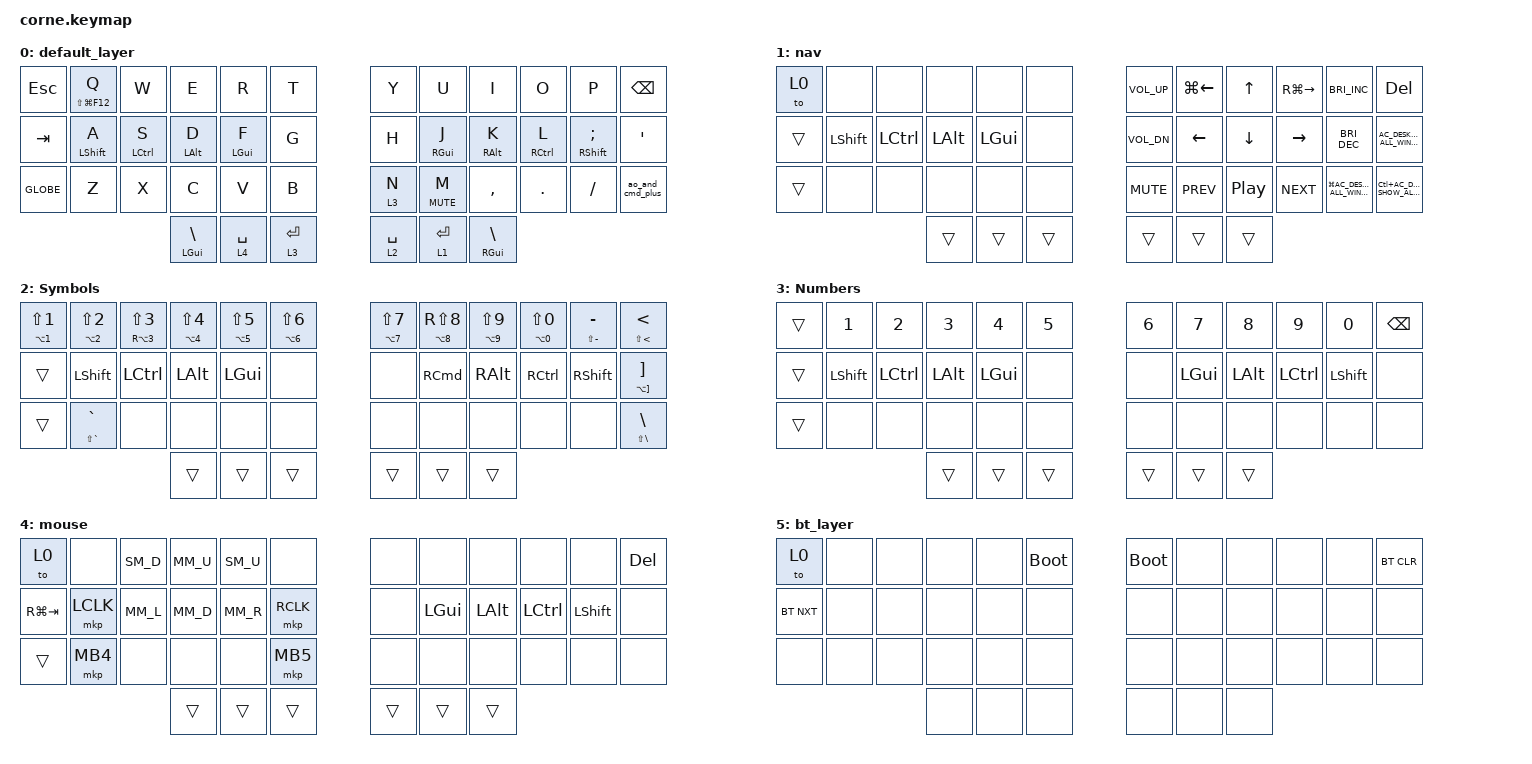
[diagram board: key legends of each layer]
/*
 * Copyright (c) 2020 The ZMK Contributors
 *
 * SPDX-License-Identifier: MIT
 */

#include <dt-bindings/zmk/mouse.h>
#include <behaviors.dtsi>
#include <dt-bindings/zmk/bt.h>
#include <dt-bindings/zmk/keys.h>
#include <dt-bindings/zmk/mouse.h>
#include <dt-bindings/zmk/pointing.h>
#include "mouse.dtsi"

/ {
    behaviors {
        temp_layer: temp_layer {
            compatible = "zmk,behavior-hold-tap";
            label = "TEMP_LAYER";
            bindings = <&mo>, <&kp>;

            #binding-cells = <2>;
            tapping-term-ms = <250>;
            flavor = "tap-preferred";
        };

        hold_btn: hold_btn {
            compatible = "zmk,behavior-hold-tap";
            label = "HOLD_BTN";
            bindings = <&kp>, <&kp>;

            #binding-cells = <2>;
            tapping-term-ms = <250>;
            flavor = "tap-preferred";
        };

        hold_and_release: hold_and_release {
            compatible = "zmk,behavior-hold-tap";
            label = "HOLD_AND_RELEASE";
            bindings = <&kp>, <&kp>;

            #binding-cells = <2>;
            tapping-term-ms = <200>;
            hold-trigger-on-release;
        };

        ao_and_cmd_plus: ao_and_cmd_plus {
            compatible = "zmk,behavior-mod-morph";
            label = "AO_AND_CMD_PLUS";
            bindings = <&kp LEFT_BRACKET>, <&kp LG(MINUS)>;

            #binding-cells = <0>;
            mods = <(MOD_LGUI|MOD_RGUI)>;
        };
    };

    combos {
        compatible = "zmk,combos";

        bt_layer {
            bindings = <&tog 5>;
            key-positions = <38 39>;
            layers = <0 6>;
        };

        left_paranthesis {
            bindings = <&kp LS(N8)>;
            key-positions = <9 8>;
            layers = <0>;
            timeout-ms = <40>;
        };

        right_paranthesis {
            bindings = <&kp LS(N9)>;
            key-positions = <9 10>;
            layers = <0>;
            timeout-ms = <40>;
        };

        left_bracket {
            bindings = <&kp LA(N8)>;
            key-positions = <21 20>;
            layers = <0>;
            timeout-ms = <40>;
        };

        left_curly_bracket {
            bindings = <&kp LS(LA(N8))>;
            key-positions = <33 32>;
            layers = <0>;
            timeout-ms = <40>;
        };

        right_bracket {
            bindings = <&kp LA(N9)>;
            key-positions = <21 22>;
            layers = <0>;
            timeout-ms = <40>;
        };

        right_curly_bracket {
            bindings = <&kp RA(RS(N9))>;
            key-positions = <33 34>;
            layers = <0>;
            timeout-ms = <40>;
        };

        less_than {
            bindings = <&kp GRAVE>;
            key-positions = <7 6>;
            layers = <0>;
            timeout-ms = <40>;
        };

        more_than {
            bindings = <&kp TILDE>;
            key-positions = <19 18>;
            layers = <0>;
            timeout-ms = <40>;
        };

        b_slash {
            bindings = <&kp LS(LA(N7))>;
            key-positions = <31 32>;
            layers = <0>;
            timeout-ms = <40>;
        };

        f_slash {
            bindings = <&kp LS(N7)>;
            key-positions = <7 8>;
            layers = <0>;
            timeout-ms = <40>;
        };

        pipe {
            bindings = <&kp LA(N7)>;
            key-positions = <19 20>;
            layers = <0>;
            timeout-ms = <40>;
        };

        minus {
            bindings = <&kp SLASH>;
            key-positions = <30 31>;
            layers = <0>;
            timeout-ms = <40>;
        };

        plus {
            bindings = <&kp MINUS>;
            key-positions = <30 32>;
            layers = <0>;
            timeout-ms = <40>;
        };

        sticky_layer_2 {
            bindings = <&tog 4>;
            key-positions = <37 38 36>;
            layers = <0 5>;
        };

        sticky_layer_1 {
            bindings = <&tog 1>;
            key-positions = <40 39 41>;
            layers = <0 1>;
        };
    };

    keymap {
        compatible = "zmk,keymap";

        default_layer {
            // -----------------------------------------------------------------------------------------
            // |  ESC |  Q  |  W  |  E  |  R  |  T  |   |  Y  |  U  |  I  |  O  |  P  | BSPC |
            // |  TAB |  A  |  S  |  D  |  F  |  G  |   |  H  |  J  |  K  |  L  |  ;  |  '   |
            // | GLOB |  Z  |  X  |  C  |  V  |  B  |   |  N  |  M  |  ,  |  .  |  /  |  [   |
            //                    |\GUI |SPC/4|ENT/3|   |SPC/2|ENT/1|\RGUI|
            // Hold: Q=⌘⇧F12  Home row: A=SHFT S=CTRL D=ALT F=GUI / J=GUI K=ALT L=CTRL ;=SHFT
            // Hold: N=MO(3)  M=MUTE  [=⌘-

            bindings = <
&kp ESC    &hold_btn LS(LG(F12)) Q  &kp W                     &kp E                     &kp R                 &kp T                  &kp Y                &kp U                  &kp I                          &kp O                      &kp P                            &kp BSPC
&kp TAB    &hold_btn LSHFT A        &hold_btn LEFT_CONTROL S  &hold_btn LEFT_ALT D      &hold_btn LEFT_GUI F  &kp G                  &kp H                &hold_btn RIGHT_GUI J  &hold_btn RIGHT_ALT K          &hold_btn RIGHT_CONTROL L  &hold_btn RIGHT_SHIFT SEMICOLON  &kp SQT
&kp GLOBE  &kp Z                    &kp X                     &kp C                     &kp V                 &kp B                  &temp_layer 3 N      &hold_btn K_MUTE M     &kp COMMA                      &kp PERIOD                 &kp FSLH                         &ao_and_cmd_plus
                                                              &hold_btn LGUI BACKSLASH  &temp_layer 4 SPACE   &temp_layer 3 ENTER    &temp_layer 2 SPACE  &temp_layer 1 ENTER    &hold_btn RIGHT_GUI BACKSLASH
            >;
        };

        nav {
            // -----------------------------------------------------------------------------------------
            // | TO0 |     |     |     |     |     |   | V+  | ⌘←  |  ↑  | ⌘→  | BRI+| DEL  |
            // | --- |SHFT |CTRL | ALT | GUI |     |   | V-  |  ←  |  ↓  |  →  | BRI-| MSCT |
            // | --- |     |     |     |     |     |   |MUTE |PREV | PLY |NEXT |⌘MSC |⌃MSC  |
            //                    | --- | --- | --- |   | --- | --- | --- |

            bindings = <
&to 0   &none           &none             &none         &none         &none     &kp C_VOLUME_UP  &kp LG(LEFT_ARROW)  &kp UP_ARROW      &kp RG(RIGHT)  &kp C_BRIGHTNESS_INC                   &kp DEL
&trans  &kp LEFT_SHIFT  &kp LEFT_CONTROL  &kp LEFT_ALT  &kp LEFT_GUI  &none     &kp C_VOL_DN     &kp LEFT            &kp DOWN_ARROW    &kp RIGHT      &kp C_BRI_DEC                          &kp C_AC_DESKTOP_SHOW_ALL_WINDOWS
&trans  &none           &none             &none         &none         &none     &kp K_MUTE       &kp C_PREV          &kp C_PLAY_PAUSE  &kp C_NEXT     &kp LG(C_AC_DESKTOP_SHOW_ALL_WINDOWS)  &kp LC(C_AC_DESKTOP_SHOW_ALL_WINDOWS)
                                          &trans        &trans        &trans    &trans           &trans              &trans
            >;
        };

        Symbols {
            // -----------------------------------------------------------------------------------------
            // |  !  |  @  |  #  |  $  |  %  |  ^  |   |  &  |  *  |  (  |  )  |  -  |  <  |
            // | --- |SHFT |CTRL | ALT | GUI |     |   |     |RGUI |RALT |RCTL |RSHT |  ]  |
            // | --- |  `  |     |     |     |     |   |     |     |     |     |     |  \  |
            //                    | --- | --- | --- |   | --- | --- | --- |
            // Hold: row1 = Alt+number (Mac special chars)  ] hold=LA(])  \ hold=LS(\)=|  ` hold=~

            bindings = <
&hold_btn LA(NUMBER_1) LS(NUMBER_1)  &hold_btn LA(NUMBER_2) LS(NUMBER_2)  &hold_btn RA(NUMBER_3) LS(NUMBER_3)  &hold_btn LA(NUMBER_4) LS(NUMBER_4)  &hold_btn LA(N5) LS(N5)  &hold_btn LA(NUMBER_6) LS(NUMBER_6)    &hold_btn LA(N7) LS(N7)  &hold_btn LA(N8) RS(N8)  &hold_btn LA(N9) LS(N9)  &hold_btn LA(N0) LS(N0)  &hold_btn LS(MINUS) MINUS  &hold_btn LS(LESS_THAN) LESS_THAN
&trans                               &kp LEFT_SHIFT                       &kp LEFT_CONTROL                     &kp LEFT_ALT                         &kp LEFT_GUI             &none                                  &none                    &kp RIGHT_COMMAND        &kp RIGHT_ALT            &kp RIGHT_CONTROL        &kp RIGHT_SHIFT            &hold_btn LA(RIGHT_BRACKET) RIGHT_BRACKET
&trans                               &hold_btn LS(GRAVE) GRAVE            &none                                &none                                &none                    &none                                  &none                    &none                    &none                    &none                    &none                      &hold_and_release LS(BACKSLASH) BACKSLASH
                                                                                                               &trans                               &trans                   &trans                                 &trans                   &trans                   &trans
            >;
        };

        Numbers {
            // -----------------------------------------------------------------------------------------
            // | --- |  1  |  2  |  3  |  4  |  5  |   |  6  |  7  |  8  |  9  |  0  | BSPC |
            // | --- |SHFT |CTRL | ALT | GUI |     |   |     | GUI | ALT |CTRL |SHFT |     |
            // | --- |     |     |     |     |     |   |     |     |     |     |     |     |
            //                    | --- | --- | --- |   | --- | --- | --- |

            bindings = <
&trans  &kp NUMBER_1  &kp NUMBER_2  &kp NUMBER_3  &kp NUMBER_4  &kp N5    &kp NUMBER_6  &kp N7    &kp N8    &kp N9     &kp N0     &kp BSPC
&trans  &kp LSHFT     &kp LCTRL     &kp LALT      &kp LGUI      &none     &none         &kp LGUI  &kp LALT  &kp LCTRL  &kp LSHFT  &none
&trans  &none         &none         &none         &none         &none     &none         &none     &none     &none      &none      &none
                                    &trans        &trans        &trans    &trans        &trans    &trans
            >;
        };

        mouse {
            // -----------------------------------------------------------------------------------------
            // | TO0 |     |SCR↓ | MM↑ |SCR↑ |     |   |     |     |     |     |     | DEL  |
            // |⌘TAB |LCLK | MM← | MM↓ | MM→ |RCLK |   |     | GUI | ALT |CTRL |SHFT |     |
            // | --- | MB4 |     |     |     | MB5 |   |     |     |     |     |     |     |
            //                    | --- | --- | --- |   | --- | --- | --- |

            bindings = <
&to 0        &none      SM_D    MM_U    SM_U     &none        &none   &none          &none          &none             &none           &kp DEL
&kp RG(TAB)  &mkp LCLK  MM_L    MM_D    MM_R     &mkp RCLK    &none   &kp LEFT_GUI   &kp LEFT_ALT   &kp LEFT_CONTROL  &kp LEFT_SHIFT  &none
&trans       &mkp MB4   &none   &none   &none    &mkp MB5     &none   &none          &none          &none             &none           &none
                                &trans   &trans  &trans       &trans  &trans         &trans
            >;
        };

        bt_layer {
            // -----------------------------------------------------------------------------------------
            // | TO0 |     |     |     |     |BOOT |   |BOOT |     |     |     |     |BTCLR |
            // |BTNXT|     |     |     |     |     |   |     |     |     |     |     |      |
            // |     |     |     |     |     |     |   |     |     |     |     |     |      |
            //                    |     |     |     |   |     |     |     |

            bindings = <
&to 0       &none  &none  &none  &none  &bootloader    &bootloader  &none  &none  &none  &none  &bt BT_CLR
&bt BT_NXT  &none  &none  &none  &none  &none          &none        &none  &none  &none  &none  &none
&none       &none  &none  &none  &none  &none          &none        &none  &none  &none  &none  &none
                          &none  &none  &none          &none        &none  &none
            >;
        };
    };
};
